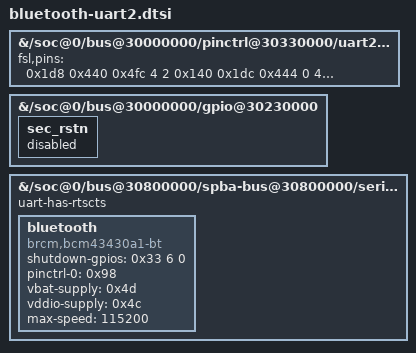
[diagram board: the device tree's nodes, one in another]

&{/soc@0/bus@30000000/pinctrl@30330000/uart2grp} {
 fsl,pins = <0x1d8 0x440 0x4fc 4 2 0x140 0x1dc 0x444 0 4 0 0x140 0x1d0 0x438 0 4 0 0x140 0x1d4 0x43c 0x4f8 4 3 0x140>;
};
&{/soc@0/bus@30000000/gpio@30230000} {
 /delete-property/ pinctrl-0;
 sec_rstn { status = "disabled"; };
};
&{/soc@0/bus@30800000/spba-bus@30800000/serial@30890000} {
 uart-has-rtscts;
 bluetooth {
  compatible = "brcm,bcm43430a1-bt";
  status = "okay";
  shutdown-gpios = <0x33 6 0>;
  pinctrl-names = "default";
  pinctrl-0 = <0x98>;
  vbat-supply = <0x4d>;
  vddio-supply = <0x4c>;
  max-speed = <115200>;
 };
};
